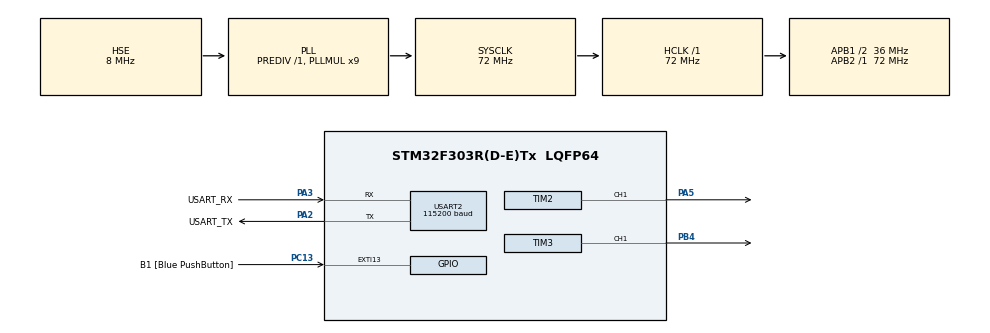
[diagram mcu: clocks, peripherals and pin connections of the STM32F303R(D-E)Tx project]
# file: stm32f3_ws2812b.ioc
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Dma.Request0=USART2_TX
Dma.Request1=TIM2_CH1
Dma.Request2=TIM3_CH1/TRIG
Dma.TIM2_CH1.1.Direction=DMA_MEMORY_TO_PERIPH
Dma.TIM2_CH1.1.Instance=DMA1_Channel5
Dma.TIM2_CH1.1.MemDataAlignment=DMA_MDATAALIGN_WORD
Dma.TIM2_CH1.1.MemInc=DMA_MINC_ENABLE
Dma.TIM2_CH1.1.Mode=DMA_NORMAL
Dma.TIM2_CH1.1.PeriphDataAlignment=DMA_PDATAALIGN_WORD
Dma.TIM2_CH1.1.PeriphInc=DMA_PINC_DISABLE
Dma.TIM2_CH1.1.Priority=DMA_PRIORITY_LOW
Dma.TIM3_CH1/TRIG.2.Direction=DMA_MEMORY_TO_PERIPH
Dma.TIM3_CH1/TRIG.2.Instance=DMA1_Channel6
Dma.TIM3_CH1/TRIG.2.MemDataAlignment=DMA_MDATAALIGN_HALFWORD
Dma.TIM3_CH1/TRIG.2.MemInc=DMA_MINC_ENABLE
Dma.TIM3_CH1/TRIG.2.Mode=DMA_NORMAL
Dma.TIM3_CH1/TRIG.2.PeriphDataAlignment=DMA_PDATAALIGN_HALFWORD
Dma.TIM3_CH1/TRIG.2.PeriphInc=DMA_PINC_DISABLE
Dma.TIM3_CH1/TRIG.2.Priority=DMA_PRIORITY_LOW
Dma.USART2_TX.0.Direction=DMA_MEMORY_TO_PERIPH
Dma.USART2_TX.0.Instance=DMA1_Channel7
Dma.USART2_TX.0.MemDataAlignment=DMA_MDATAALIGN_BYTE
Dma.USART2_TX.0.MemInc=DMA_MINC_ENABLE
Dma.USART2_TX.0.Mode=DMA_NORMAL
Dma.USART2_TX.0.PeriphDataAlignment=DMA_PDATAALIGN_BYTE
Dma.USART2_TX.0.PeriphInc=DMA_PINC_DISABLE
Dma.USART2_TX.0.Priority=DMA_PRIORITY_LOW
Mcu.Family=STM32F3
Mcu.Name=STM32F303R(D-E)Tx
Mcu.Package=LQFP64
Mcu.UserConstants=configTIM2_PERIOD,2000
NVIC.DMA1_Channel5_IRQn=true\:0\:0\:false\:false\:true\:false\:true
NVIC.DMA1_Channel6_IRQn=true\:0\:0\:false\:false\:true\:false\:true
NVIC.DMA1_Channel7_IRQn=true\:0\:0\:false\:false\:true\:false\:true
NVIC.PriorityGroup=NVIC_PRIORITYGROUP_0
PA13.GPIO_Label=TMS
PA13.Mode=Serial_Wire
PA13.Signal=SYS_JTMS-SWDIO
PA14.GPIO_Label=TCK
PA14.Mode=Serial_Wire
PA14.Signal=SYS_JTCK-SWCLK
PA2.GPIO_Label=USART_TX
PA2.GPIO_Mode=GPIO_MODE_AF_PP
PA2.GPIO_PuPd=GPIO_NOPULL
PA2.GPIO_Speed=GPIO_SPEED_FREQ_LOW
PA2.Mode=Asynchronous
PA2.Signal=USART2_TX
PA3.GPIO_Label=USART_RX
PA3.GPIO_Mode=GPIO_MODE_AF_PP
PA3.GPIO_PuPd=GPIO_NOPULL
PA3.GPIO_Speed=GPIO_SPEED_FREQ_LOW
PA3.Mode=Asynchronous
PA3.Signal=USART2_RX
PA5.Signal=S_TIM2_CH1_ETR
PB3.GPIO_Label=SWO
PB3.Signal=SYS_JTDO-TRACESWO
PB4.GPIO_Speed=GPIO_SPEED_FREQ_HIGH
PB4.Signal=S_TIM3_CH1
PC13.GPIO_Label=B1 [Blue PushButton]
PC13.GPIO_ModeDefaultEXTI=GPIO_MODE_IT_FALLING
PC13.Signal=GPXTI13
PC14-OSC32_IN.Mode=LSE-External-Oscillator
PC14-OSC32_IN.Signal=RCC_OSC32_IN
PC15-OSC32_OUT.Mode=LSE-External-Oscillator
PC15-OSC32_OUT.Signal=RCC_OSC32_OUT
PF0-OSC_IN.Mode=HSE-External-Oscillator
PF0-OSC_IN.Signal=RCC_OSC_IN
PF1-OSC_OUT.Mode=HSE-External-Oscillator
PF1-OSC_OUT.Signal=RCC_OSC_OUT
ProjectManager.HeapSize=0x200
ProjectManager.StackSize=0x400
ProjectManager.TargetToolchain=SW4STM32
RCC.AHBFreq_Value=72000000
RCC.APB1CLKDivider=RCC_HCLK_DIV2
RCC.APB1Freq_Value=36000000
RCC.APB1TimFreq_Value=72000000
RCC.APB2Freq_Value=72000000
RCC.APB2TimFreq_Value=72000000
RCC.CortexFreq_Value=72000000
RCC.HCLKFreq_Value=72000000
RCC.HSE_VALUE=8000000
RCC.HSI_VALUE=8000000
RCC.PLLM=8
RCC.PLLMUL=RCC_PLL_MUL9
RCC.PLLN=336
RCC.PLLP=RCC_PLLP_DIV4
RCC.PLLQ=7
RCC.PLLSourceVirtual=RCC_PLLSOURCE_HSE
RCC.RCC_PLLsource_Clock_Source_FROM_HSE=RCC_HSE_PREDIV_DIV2
RCC.SYSCLKFreq_VALUE=72000000
RCC.SYSCLKSourceVirtual=RCC_SYSCLKSOURCE_PLLCLK
RCC.USBFreq_Value=72000000
SH.S_TIM2_CH1_ETR.0=TIM2_CH1,PWM Generation1 CH1
SH.S_TIM3_CH1.0=TIM3_CH1,PWM Generation1 CH1
TIM2.AutoReloadPreload=TIM_AUTORELOAD_PRELOAD_ENABLE
TIM2.Channel-PWM\ Generation1\ CH1=TIM_CHANNEL_1
TIM2.ClockDivision=TIM_CLOCKDIVISION_DIV1
TIM2.Period=configTIM2_PERIOD-1
TIM2.Prescaler=36000-1
TIM3.Channel-PWM\ Generation1\ CH1=TIM_CHANNEL_1
TIM3.Period=10-1
TIM3.Prescaler=9-1
USART2.BaudRate=115200
USART2.VirtualMode-Asynchronous=VM_ASYNC
VP_TIM2_VS_ClockSourceINT.Mode=Internal
VP_TIM3_VS_ClockSourceINT.Mode=Internal
board=NUCLEO-F303RE

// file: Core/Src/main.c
/* USER CODE BEGIN Header */
/**
  ******************************************************************************
  * @file           : main.c
  * @brief          : Main program body
  ******************************************************************************
  * @attention
  *
  * <h2><center>&copy; Copyright (c) 2019 STMicroelectronics.
  * All rights reserved.</center></h2>
  *
  * This software component is licensed by ST under BSD 3-Clause license,
  * the "License"; You may not use this file except in compliance with the
  * License. You may obtain a copy of the License at:
  *                        opensource.org/licenses/BSD-3-Clause
  *
  ******************************************************************************
  */
/* USER CODE END Header */

#include "main.h"
#include "dma.h"
#include "tim.h"
#include "usart.h"
#include "gpio.h"

/* USER CODE BEGIN Includes */
#include "string.h"

/* USER CODE END Includes */

void SystemClock_Config(void);
/* USER CODE BEGIN PFP */
extern void app_main(void);

/* USER CODE END PFP */

int main(void)
{

  /* MCU Configuration--------------------------------------------------------*/

  /* Reset of all peripherals, Initializes the Flash interface and the Systick. */
  HAL_Init();

  /* Configure the system clock */
  SystemClock_Config();

  /* Initialize all configured peripherals */
  MX_GPIO_Init();
  MX_DMA_Init();
  MX_TIM2_Init();
  MX_USART2_UART_Init();
  MX_TIM3_Init();

  /* Infinite loop */
  /* USER CODE BEGIN WHILE */

  static char message_buf[64];
  memset(message_buf, '\0', 64);

  strcpy(message_buf, "OK!\n");
  HAL_UART_Transmit_DMA(&huart2, (uint8_t *)message_buf, strnlen(message_buf, 64));

  static uint32_t led_pulse_width = 0.5 * configTIM2_PERIOD;
  HAL_TIM_Base_Start(&htim2);

  if (HAL_TIM_PWM_Start_DMA(&htim2, TIM_CHANNEL_1, (uint32_t *)&led_pulse_width, 1) != HAL_OK) {
      strcpy(message_buf, "ERROR!\n");
      HAL_UART_Transmit_DMA(&huart2, (uint8_t *)message_buf, strnlen(message_buf, 64));
  }

  app_main();

  while (1)
  {
    /* USER CODE END WHILE */

  }
}

void SystemClock_Config(void)
{
  RCC_OscInitTypeDef RCC_OscInitStruct = {0};
  RCC_ClkInitTypeDef RCC_ClkInitStruct = {0};
  RCC_PeriphCLKInitTypeDef PeriphClkInit = {0};

  /** Initializes the CPU, AHB and APB busses clocks
  */
  RCC_OscInitStruct.OscillatorType = RCC_OSCILLATORTYPE_HSE;
  RCC_OscInitStruct.HSEState = RCC_HSE_ON;
  RCC_OscInitStruct.HSIState = RCC_HSI_ON;
  RCC_OscInitStruct.PLL.PLLState = RCC_PLL_ON;
  RCC_OscInitStruct.PLL.PLLSource = RCC_PLLSOURCE_HSE;
  RCC_OscInitStruct.PLL.PLLMUL = RCC_PLL_MUL9;
  RCC_OscInitStruct.PLL.PREDIV = RCC_PREDIV_DIV1;
  if (HAL_RCC_OscConfig(&RCC_OscInitStruct) != HAL_OK)
  {
    Error_Handler();
  }
  /** Initializes the CPU, AHB and APB busses clocks
  */
  RCC_ClkInitStruct.ClockType = RCC_CLOCKTYPE_HCLK|RCC_CLOCKTYPE_SYSCLK
                              |RCC_CLOCKTYPE_PCLK1|RCC_CLOCKTYPE_PCLK2;
  RCC_ClkInitStruct.SYSCLKSource = RCC_SYSCLKSOURCE_PLLCLK;
  RCC_ClkInitStruct.AHBCLKDivider = RCC_SYSCLK_DIV1;
  RCC_ClkInitStruct.APB1CLKDivider = RCC_HCLK_DIV2;
  RCC_ClkInitStruct.APB2CLKDivider = RCC_HCLK_DIV1;

  if (HAL_RCC_ClockConfig(&RCC_ClkInitStruct, FLASH_LATENCY_2) != HAL_OK)
  {
    Error_Handler();
  }
  PeriphClkInit.PeriphClockSelection = RCC_PERIPHCLK_USART2|RCC_PERIPHCLK_TIM2
                              |RCC_PERIPHCLK_TIM34;
  PeriphClkInit.Usart2ClockSelection = RCC_USART2CLKSOURCE_PCLK1;
  PeriphClkInit.Tim2ClockSelection = RCC_TIM2CLK_HCLK;
  PeriphClkInit.Tim34ClockSelection = RCC_TIM34CLK_HCLK;
  if (HAL_RCCEx_PeriphCLKConfig(&PeriphClkInit) != HAL_OK)
  {
    Error_Handler();
  }
}

void Error_Handler(void)
{
}

/************************ (C) COPYRIGHT STMicroelectronics *****END OF FILE****/
